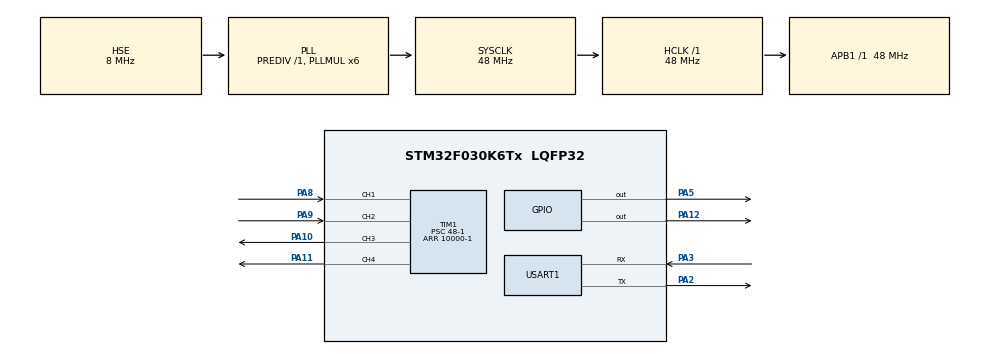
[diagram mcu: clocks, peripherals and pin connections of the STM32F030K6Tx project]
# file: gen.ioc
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Mcu.Family=STM32F0
Mcu.Name=STM32F030K6Tx
Mcu.Package=LQFP32
NVIC.TIM1_CC_IRQn=true\:0\:0\:false\:false\:true\:true\:true
NVIC.TIM3_IRQn=true\:0\:0\:false\:false\:true\:false\:true
NVIC.TimeBase=TIM3_IRQn
NVIC.TimeBaseIP=TIM3
PA10.Signal=S_TIM1_CH3
PA11.Signal=S_TIM1_CH4
PA12.Signal=GPIO_Output
PA13.Mode=Serial_Wire
PA13.Signal=SYS_SWDIO
PA14.Mode=Serial_Wire
PA14.Signal=SYS_SWCLK
PA2.Mode=Asynchronous
PA2.Signal=USART1_TX
PA3.Mode=Asynchronous
PA3.Signal=USART1_RX
PA5.Signal=GPIO_Output
PA8.Signal=S_TIM1_CH1
PA9.Signal=S_TIM1_CH2
PF0-OSC_IN.Mode=HSE-External-Oscillator
PF0-OSC_IN.Signal=RCC_OSC_IN
PF1-OSC_OUT.Mode=HSE-External-Oscillator
PF1-OSC_OUT.Signal=RCC_OSC_OUT
ProjectManager.HeapSize=0x200
ProjectManager.StackSize=0x400
ProjectManager.TargetToolchain=SW4STM32
RCC.AHBFreq_Value=48000000
RCC.APB1Freq_Value=48000000
RCC.APB1TimFreq_Value=48000000
RCC.HCLKFreq_Value=48000000
RCC.PLLMUL=RCC_PLL_MUL6
RCC.PLLSourceVirtual=RCC_PLLSOURCE_HSE
RCC.SYSCLKFreq_VALUE=48000000
RCC.SYSCLKSource=RCC_SYSCLKSOURCE_PLLCLK
SH.S_TIM1_CH1.0=TIM1_CH1,Input_Capture1_from_TI1
SH.S_TIM1_CH2.0=TIM1_CH2,Input_Capture2_from_TI2
SH.S_TIM1_CH3.0=TIM1_CH3,PWM Generation3 CH3
SH.S_TIM1_CH4.0=TIM1_CH4,PWM Generation4 CH4
TIM1.Channel-Input_Capture1_from_TI1=TIM_CHANNEL_1
TIM1.Channel-Input_Capture2_from_TI2=TIM_CHANNEL_2
TIM1.Channel-PWM\ Generation3\ CH3=TIM_CHANNEL_3
TIM1.Channel-PWM\ Generation4\ CH4=TIM_CHANNEL_4
TIM1.ICPolarity_CH1=TIM_INPUTCHANNELPOLARITY_BOTHEDGE
TIM1.ICPolarity_CH2=TIM_INPUTCHANNELPOLARITY_BOTHEDGE
TIM1.Period=10000-1
TIM1.Prescaler=48-1
USART1.VirtualMode-Asynchronous=VM_ASYNC
VP_SYS_VS_tim3.Mode=TIM3
board=custom

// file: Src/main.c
/* USER CODE BEGIN Header */
/**
  ******************************************************************************
  * @file           : main.c
  * @brief          : Main program body
  ******************************************************************************
  * @attention
  *
  * <h2><center>&copy; Copyright (c) 2020 STMicroelectronics.
  * All rights reserved.</center></h2>
  *
  * This software component is licensed by ST under BSD 3-Clause license,
  * the "License"; You may not use this file except in compliance with the
  * License. You may obtain a copy of the License at:
  *                        opensource.org/licenses/BSD-3-Clause
  *
  ******************************************************************************
  */
/* USER CODE END Header */

#include "main.h"
#include "tim.h"
#include "usart.h"
#include "gpio.h"

/* USER CODE BEGIN Includes */
#include <system_init.h>
/* USER CODE END Includes */

void SystemClock_Config(void);
/* USER CODE BEGIN PFP */
extern void run(void);
/* USER CODE END PFP */

int main(void)
{

  /* MCU Configuration--------------------------------------------------------*/

  /* Reset of all peripherals, Initializes the Flash interface and the Systick. */
  HAL_Init();

  /* Configure the system clock */
  SystemClock_Config();

  /* USER CODE BEGIN SysInit */
  system_init();
  /* USER CODE END SysInit */

  /* Initialize all configured peripherals */
  MX_GPIO_Init();
  MX_TIM1_Init();
  MX_USART1_UART_Init();
  /* USER CODE BEGIN 2 */
  tim_start();
  /* USER CODE END 2 */

  /* Infinite loop */
  /* USER CODE BEGIN WHILE */
  run();
    /* USER CODE END WHILE */

}

void SystemClock_Config(void)
{
  RCC_OscInitTypeDef RCC_OscInitStruct = {0};
  RCC_ClkInitTypeDef RCC_ClkInitStruct = {0};
  RCC_PeriphCLKInitTypeDef PeriphClkInit = {0};

  /** Initializes the CPU, AHB and APB busses clocks
  */
  RCC_OscInitStruct.OscillatorType = RCC_OSCILLATORTYPE_HSE;
  RCC_OscInitStruct.HSEState = RCC_HSE_ON;
  RCC_OscInitStruct.PLL.PLLState = RCC_PLL_ON;
  RCC_OscInitStruct.PLL.PLLSource = RCC_PLLSOURCE_HSE;
  RCC_OscInitStruct.PLL.PLLMUL = RCC_PLL_MUL6;
  RCC_OscInitStruct.PLL.PREDIV = RCC_PREDIV_DIV1;
  if (HAL_RCC_OscConfig(&RCC_OscInitStruct) != HAL_OK)
  {
    Error_Handler();
  }
  /** Initializes the CPU, AHB and APB busses clocks
  */
  RCC_ClkInitStruct.ClockType = RCC_CLOCKTYPE_HCLK|RCC_CLOCKTYPE_SYSCLK
                              |RCC_CLOCKTYPE_PCLK1;
  RCC_ClkInitStruct.SYSCLKSource = RCC_SYSCLKSOURCE_PLLCLK;
  RCC_ClkInitStruct.AHBCLKDivider = RCC_SYSCLK_DIV1;
  RCC_ClkInitStruct.APB1CLKDivider = RCC_HCLK_DIV1;

  if (HAL_RCC_ClockConfig(&RCC_ClkInitStruct, FLASH_LATENCY_1) != HAL_OK)
  {
    Error_Handler();
  }
  PeriphClkInit.PeriphClockSelection = RCC_PERIPHCLK_USART1;
  PeriphClkInit.Usart1ClockSelection = RCC_USART1CLKSOURCE_PCLK1;
  if (HAL_RCCEx_PeriphCLKConfig(&PeriphClkInit) != HAL_OK)
  {
    Error_Handler();
  }
}

void HAL_TIM_PeriodElapsedCallback(TIM_HandleTypeDef *htim)
{
  if (htim->Instance == TIM3) {
    HAL_IncTick();
  }
}

void Error_Handler(void)
{
  __disable_irq();
  while (1) {}
}

/************************ (C) COPYRIGHT STMicroelectronics *****END OF FILE****/
